# A31G22x register map
Vendor: ABOV Semiconductor Co., Ltd.; Series: A31G22x; File version: 0.2
CPU: CM0PLUS r0p1, little endian, no MPU, no FPU, VTOR, 2 interrupt priority bits
Registers are 32-bit, read-write, reset 0x0 unless marked. A register's access mark holds for its fields unless they carry their own. Offsets are from the block's base; [hi:lo] are bit positions; {n}, {i} and the like mark numbered series.

## SCU — SYSTEM CONTROL UNIT
Base 0x40000000
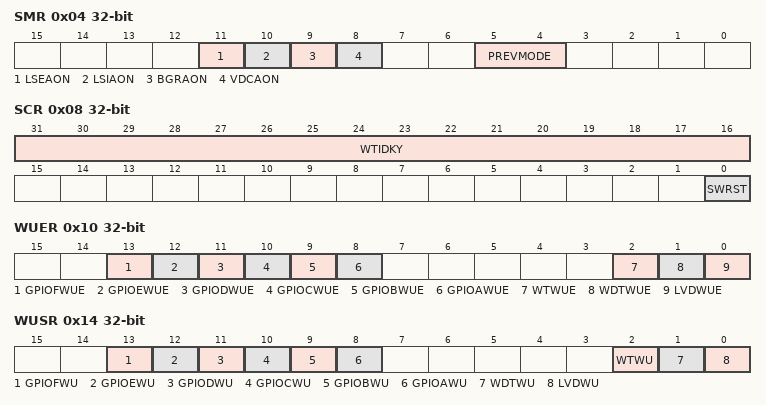
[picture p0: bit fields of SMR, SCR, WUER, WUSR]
0x04 SMR — System Mode Register
  [11] LSEAON — LSE Always on select bit in power down mode 0: LSE is automatically off entering power down mode 1: LSE isn't automatically off entering power down mode
  [10] LSIAON — LSI Always on select bit in power down mode 0: LSI is automatically off entering power down mode 1: LSI isn't automatically off entering power down mode
  [9] BGRAON — BGR Always on select bit in power down mode 0: BGR is automatically off entering power down mode 1: BGR isn't automatically off entering power down mode
  [8] VDCAON — VDC Always on select bit in power down mode
  [5:4] PREVMODE — Previous operating mode before current reset event
0x08 SCR — System Control Register
  [31:16] WTIDKY wo — On writes, write 0x9EB3 to these bits, otherwise the write is ignored.
  [0] SWRST — Internal soft reset activation bit (check RSER[4] for reset)
0x10 WUER — Wake up source enable register
  [13] GPIOFWUE — Enable wakeup source of GPIOF port pin change event
  [12] GPIOEWUE — Enable wakeup source of GPIOE port pin change event
  [11] GPIODWUE — Enable wakeup source of GPIOD port pin change event
  [10] GPIOCWUE — Enable wakeup source of GPIOC port pin change event
  [9] GPIOBWUE — Enable wakeup source of GPIOB port pin change event
  [8] GPIOAWUE — Enable wakeup source of GPIOA port pin change event
  [2] WTWUE — Enable wakeup source of watch timer event
  [1] WDTWUE — Enable wakeup source of watchdog timer event
  [0] LVDWUE — Enable wakeup source of LVD event
0x14 WUSR — Wake up source status register
  [13] GPIOFWU ro — Status of wakeup source of GPIOF port pin change event
  [12] GPIOEWU ro — Status of wakeup source of GPIOE port pin change event
  [11] GPIODWU ro — Status of wakeup source of GPIOD port pin change event
  [10] GPIOCWU ro — Status of wakeup source of GPIOC port pin change event
  [9] GPIOBWU ro — Status of wakeup source of GPIOB port pin change event
  [8] GPIOAWU ro — Status of wakeup source of GPIOA port pin change event
  [2] WTWU ro — Status of wakeup source of watch timer event
  [1] WDTWU ro — Status of wakeup source of watchdog timer event
  [0] LVDWU ro — Status of wakeup source of LVD event
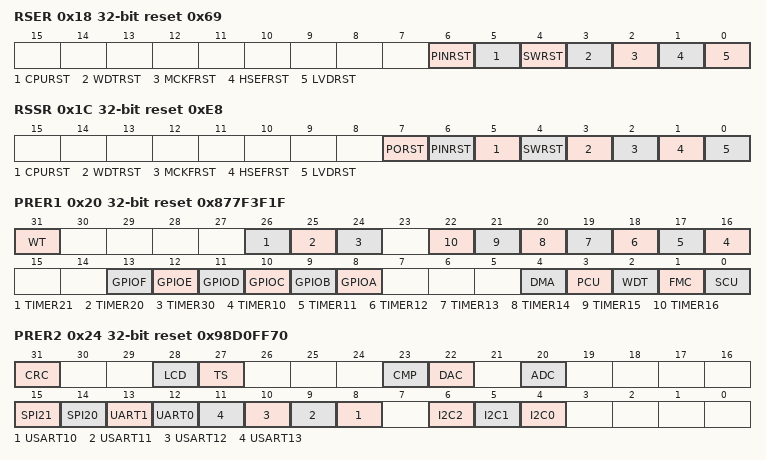
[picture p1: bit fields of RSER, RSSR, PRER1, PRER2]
0x18 RSER reset 0x69 — Reset source enable register
  [6] PINRST — External pin reset enable bit
  [5] CPURST — CPU request reset enable bit
  [4] SWRST — Software reset enable bit
  [3] WDTRST — Watchdog Timer reset enable bit
  [2] MCKFRST — MCLK Clock fail reset enable bit
  [1] HSEFRST — HSE Clock fail reset enable bit
  [0] LVDRST — LVD reset enable bit
0x1C RSSR reset 0xE8 — Reset source status register
  [7] PORST — Power on reset status bit
  [6] PINRST — External pin reset status bit
  [5] CPURST — CPU request reset status bit
  [4] SWRST — Software reset status bit
  [3] WDTRST — Watchdog Timer reset status bit
  [2] MCKFRST — MCLK Clock fail reset status bit
  [1] HSEFRST — HSE Clock fail reset status bit
  [0] LVDRST — LVD reset status bit
0x20 PRER1 reset 0x877F3F1F — Peripheral reset enable register 1
  [31] WT — WT reset mask
  [26] TIMER21 — TIMER21 reset mask
  [25] TIMER20 — TIMER20 reset mask
  [24] TIMER30 — TIMER30 reset mask
  [n+6] TIMER{n} (n=10..16) — TIMER{n} reset mask
  [13] GPIOF — GPIOF reset mask
  [12] GPIOE — GPIOE reset mask
  [11] GPIOD — GPIOD reset mask
  [10] GPIOC — GPIOC reset mask
  [9] GPIOB — GPIOB reset mask
  [8] GPIOA — GPIOA reset mask
  [4] DMA — DMA reset mask
  [3] PCU — PCU reset mask
  [2] WDT — WDT reset mask
  [1] FMC — FMC reset mask
  [0] SCU — SCU reset mask
0x24 PRER2 reset 0x98D0FF70 — Peripheral reset enable register 2
  [31] CRC — CRC reset mask
  [28] LCD — LCD reset enable
  [27] TS — Temperature Sensor reset mask
  [23] CMP — CMP reset mask
  [22] DAC — DAC reset mask
  [20] ADC — ADC reset mask
  [15] SPI21 — SPI21 reset mask
  [14] SPI20 — SPI20 reset mask
  [13] UART1 — UART1 reset mask
  [12] UART0 — UART0 reset mask
  [n-2] USART{n} (n=10..13) — USART{n} reset mask
  [6] I2C2 — I2C2 reset mask
  [5] I2C1 — I2C1 reset mask
  [4] I2C0 — I2C0 reset mask
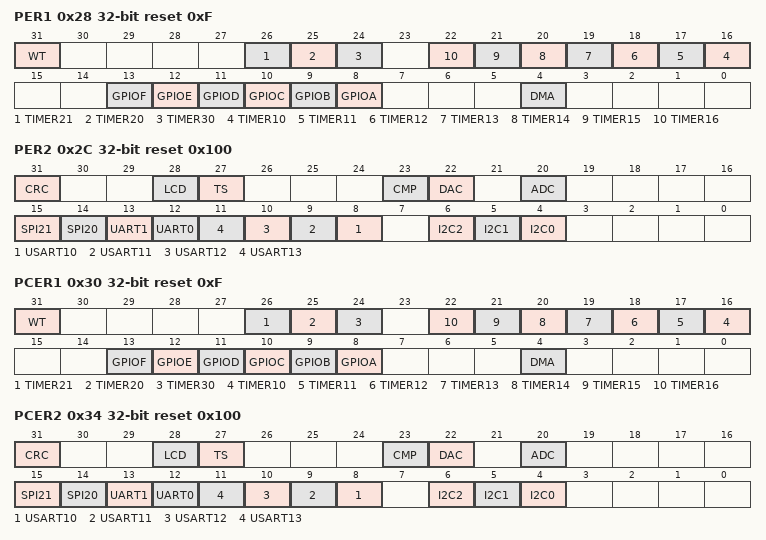
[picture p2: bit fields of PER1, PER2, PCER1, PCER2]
0x28 PER1 reset 0xF — Peripheral enable register 1
  [31] WT — WT function enable
  [26] TIMER21 — TIMER21 function enable
  [25] TIMER20 — TIMER20 function enable
  [24] TIMER30 — TIMER30 function enable
  [n+6] TIMER{n} (n=10..16) — TIMER{n} function enable
  [13] GPIOF — GPIOF function enable
  [12] GPIOE — GPIOE function enable
  [11] GPIOD — GPIOD function enable
  [10] GPIOC — GPIOC function enable
  [9] GPIOB — GPIOB function enable
  [8] GPIOA — GPIOA function enable
  [4] DMA — DMA function enable
0x2C PER2 reset 0x100 — Peripheral enable register 2
  [31] CRC — CRC function enable
  [28] LCD — LCD function enable
  [27] TS — Temperature Sensor function enable
  [23] CMP — CMP function enable
  [22] DAC — DAC function enable
  [20] ADC — ADC function enable
  [15] SPI21 — SPI21 function enable
  [14] SPI20 — SPI20 function enable
  [13] UART1 — UART1 function enable
  [12] UART0 — UART0 function enable
  [n-2] USART{n} (n=10..13) — USART{n} function enable
  [6] I2C2 — I2C2 function enable
  [5] I2C1 — I2C1 function enable
  [4] I2C0 — I2C0 function enable
0x30 PCER1 reset 0xF — Peripheral clock enable register 1
  [31] WT — WT clock enable
  [26] TIMER21 — TIMER21 clock enable
  [25] TIMER20 — TIMER20 clock enable
  [24] TIMER30 — TIMER30 clock enable
  [n+6] TIMER{n} (n=10..16) — TIMER{n} clock enable
  [13] GPIOF — GPIOF clock enable
  [12] GPIOE — GPIOE clock enable
  [11] GPIOD — GPIOD clock enable
  [10] GPIOC — GPIOC clock enable
  [9] GPIOB — GPIOB clock enable
  [8] GPIOA — GPIOA clock enable
  [4] DMA — DMA clock enable
0x34 PCER2 reset 0x100 — Peripheral clock enable register 2
  [31] CRC — CRC clock enable
  [28] LCD — LCD driver clock enable
  [27] TS — Temperature sensor clock enable
  [23] CMP — CMP clock enable
  [22] DAC — DAC clock enable
  [20] ADC — ADC clock enable
  [15] SPI21 — SPI21 clock enable
  [14] SPI20 — SPI20 clock enable
  [13] UART1 — UART1 clock enable
  [12] UART0 — UART0 clock enable
  [n-2] USART{n} (n=10..13) — USART{n} clock enable
  [6] I2C2 — I2C2 clock enable
  [5] I2C1 — I2C1 clock enable
  [4] I2C0 — I2C0 clock enable
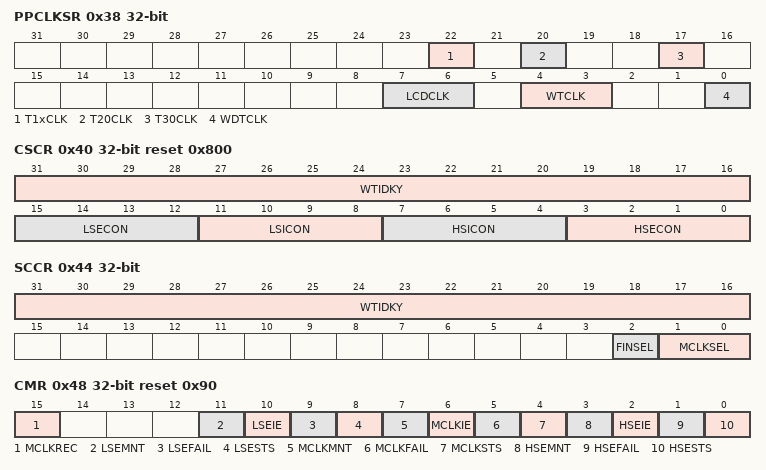
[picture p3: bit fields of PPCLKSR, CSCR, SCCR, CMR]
0x38 PPCLKSR — Peripheral clock selection register
  [22] T1xCLK — Timer 1x Clock Selection bit
  [20] T20CLK — Timer 20 Clock Selection bit
  [17] T30CLK — Timer 30 Clock Selection bit
  [7:6] LCDCLK — LCD Clock Selection bit
  [4:3] WTCLK — Watch Timer Clock Selection bit Note) These bits should be changed during the WTEN bit of watch timer control register (WTCR) is 0b
  [0] WDTCLK — Watch-dog Timer Clock Selection bit
0x40 CSCR reset 0x800 — Clock Source Control register
  [31:16] WTIDKY wo — On writes, write 0xA507 to these bits, otherwise the write is ignored.
  [15:12] LSECON — Low speed external oscillator control
  [11:8] LSICON — Low Speed Internal oscillator control
  [7:4] HSICON — High speed internal oscillator control
  [3:0] HSECON — Hight speed external oscillator control
0x44 SCCR — System Clock Control register
  [31:16] WTIDKY wo — On writes, write 0x570A to these bits, otherwise the write is ignored.
  [2] FINSEL — PLL input source FIN select register
  [1:0] MCLKSEL — System clock select register
0x48 CMR reset 0x90 — Clock Monitoring register
  [15] MCLKREC — MCLK fail auto recovery
  [11] LSEMNT — Low speed External oscillator monitoring enable
  [10] LSEIE — Low speed external oscillator fail interrupt enable
  [9] LSEFAIL — Low speed external oscillator fail interrupt
  [8] LSESTS — Low speed external oscillator status
  [7] MCLKMNT — MCLK monitoring enable
  [6] MCLKIE — MCLK fail interrupt enable
  [5] MCLKFAIL — MCLK fail interrupt
  [4] MCLKSTS — MCLK clock status
  [3] HSEMNT — High speed external oscillator monitoring enable
  [2] HSEIE — High speed external oscillator fail interrupt enable
  [1] HSEFAIL — High speed external oscillator fail interrupt
  [0] HSESTS — High speed external oscillator status
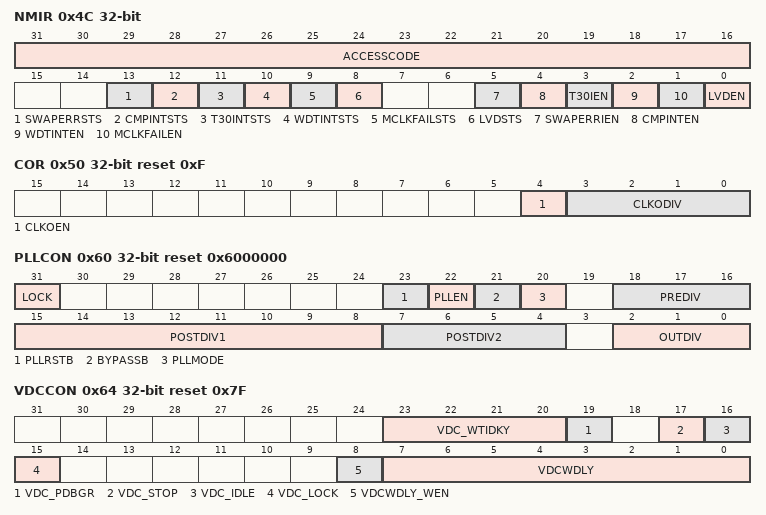
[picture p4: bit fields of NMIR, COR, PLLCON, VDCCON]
0x4C NMIR — NMI control register
  [31:16] ACCESSCODE wo — This field enables writing access to this register. Writing 0xA32C is to enable writing.
  [13] SWAPERRSTS ro — Swap Error Interrupt condition status bit This bit can't invoke NMI interrupt without enable bit
  [12] CMPINTSTS ro — Comparator Interrupt condition status bit This bit can't invoke NMI interrupt without enable bit
  [11] T30INTSTS ro — TIMER30 Interrupt condition status bit This bit can't invoke NMI interrupt without enable bit
  [10] WDTINTSTS ro — WDT Interrupt condition status bit This bit can't invoke NMI interrupt without enable bit
  [9] MCLKFAILSTS ro — MCLK Fail condition status bit This bit can't invoke NMI interrupt without enable bit
  [8] LVDSTS ro — LVD condition status bit This bit can't invoke NMI interrupt without enable bit
  [5] SWAPERRIEN — Swap Error interrupt condition enable for NMI interrupt
  [4] CMPINTEN — Comparator interrupt condition enable for NMI interrupt
  [3] T30IEN — TIMER30 interrupt condition enable for NMI interrupt
  [2] WDTINTEN — WDT Interrupt condition enable for NMI interrupt
  [1] MCLKFAILEN — MCLK Fail condition enable for NMI interrupt
  [0] LVDEN — LVD Fail condition enable for NMI interrupt
0x50 COR reset 0xF — Clock Output Control register
  [4] CLKOEN — Clock output enable
  [3:0] CLKODIV — Clock output divider value CLKO=MCLK (CLKODIV=0) CLKO=MCLK/2(CLKODIV+1) (CLKODIV > 0)
0x60 PLLCON reset 0x6000000 — PLL Control register
  [31] LOCK — LOCK status
  [23] PLLRSTB — PLL reset
  [22] PLLEN — PLL enable
  [21] BYPASSB — FIN bypass
  [20] PLLMODE — PLL VCO mode
  [18:16] PREDIV — FIN predivider FIN divided by (PREDIV + 1), (FIN/1 ~ FIN/8)
  [15:8] POSTDIV1 — Feedback control 1 (N1) N1 = POSTDIV1 + 1
  [7:4] POSTDIV2 — Feedback control 1 (N2) N2 = POSTDIV2 + 1
  [2:0] OUTDIV — output divider control (P) P = OUTDIV + 1
0x64 VDCCON reset 0x7F — VDC Control register
  [23:20] VDC_WTIDKY wo — VDC Write Identification Key On writes, write 0x5 to these bits, otherwise the write is ignored.
  [19] VDC_PDBGR — BGR Buffer Deep-sleep Signal Selection *In BGR on off, VDCLOCK_I should be 0
  [17] VDC_STOP — VDC STOP Mode Control Signal
  [16] VDC_IDLE — VDC STOP1 Mode Control Signal
  [15] VDC_LOCK — VDC VDCLOCK Control Signal for *BGR Stabilization *In BGR off on Sequence, VDCLOCK_I should be 0 during 120usec
  [8] VDCWDLY_WEN wo — VDCWDLY value write enable. VDCWDLY value can be written with writing '1' to VDCWDLY_WEN bit simultaneously.
  [7:0] VDCWDLY — VDC warm-up delay count value. When SCU is waked up from powerdown mode, the warm-up delay is inserted for VDC output being stabilized. The amount of delay can be defined with this register value 7F : 4msec
0x6C LSICON — LSI Control Register
  [0] SKIP_LS — Internal Level Shifter control signal
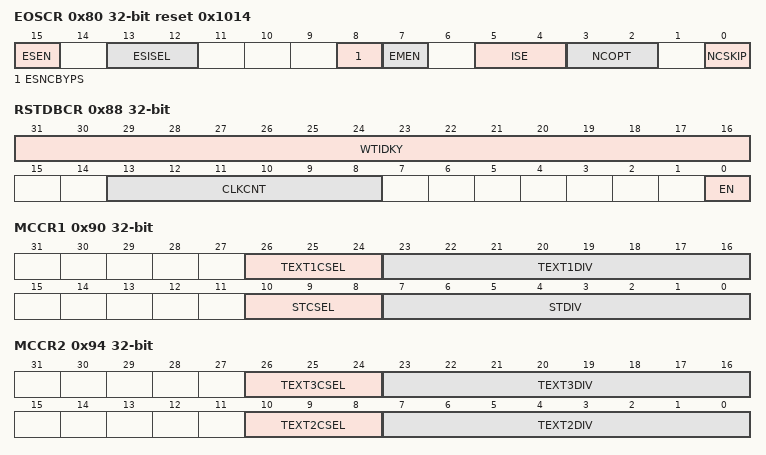
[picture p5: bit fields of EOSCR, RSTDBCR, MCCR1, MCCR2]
0x80 EOSCR reset 0x1014 — External Oscillator control register
  [15] ESEN wo — Write enable for LSE
  [13:12] ESISEL — Select current for LSE
  [8] ESNCBYPS — Noise Cancel Bypass enable for LSE
  [7] EMEN wo — Write enable for HSE
  [5:4] ISE — Select current for HSE
  [3:2] NCOPT — Noise Cancel delay Option for HSE
  [0] NCSKIP — Noise Cancel Skip enable for HSE
0x84 EMODR reset 0x1 — External mode pin read register
  [0] BOOT ro — BOOT pin level
0x88 RSTDBCR — Pin Reset Debounce Control Register
  [31:16] WTIDKY wo — On writes, write 0x0514 to these bits, otherwise the write is ignored.
  [13:8] CLKCNT — Noise cancel delay option for pin reset, N : N clock checking for debounce by LSI(500kHz)
  [0] EN — Pin reset debounce enable bit
0x90 MCCR1 — Miscellaneous Clock Control Register 1
  [26:24] TEXT1CSEL — TIMER1n EXT Clock source select bit
  [23:16] TEXT1DIV — TIMER1n EXT Clock N divider To change the value, set 0x0 first without changing TEXT1CSEL
  [10:8] STCSEL — systick clock source sel
  [7:0] STDIV — SYSTICK Clock N divider To change the value, set 0x0 first without changing STCSEL
0x94 MCCR2 — Miscellaneous Clock Control Register 2
  [26:24] TEXT3CSEL — TIMER 30 EXT Clock source select bit
  [23:16] TEXT3DIV — TIMER 30 EXT Clock N divider To change the value, set 0x0 first without changing TEXT3DIV
  [10:8] TEXT2CSEL
  [7:0] TEXT2DIV — TIMER 20 EXT Clock N divider To change the value, set 0x0 first without changing TEXT2CSEL
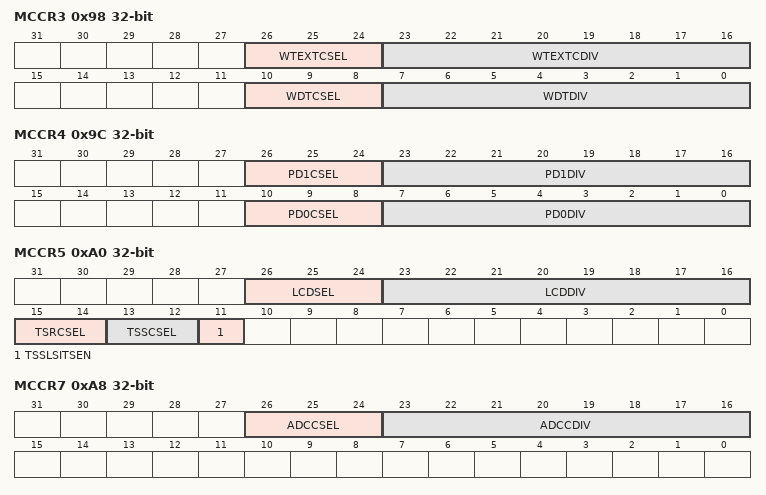
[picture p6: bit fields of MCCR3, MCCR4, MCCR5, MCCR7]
0x98 MCCR3 — Miscellaneous Clock Control Register 3
  [26:24] WTEXTCSEL — WT EXT Clock source select bit
  [23:16] WTEXTCDIV — WT EXT Clock N divider To change the value, set 0x0 first without changing WTEXTCSEL
  [10:8] WDTCSEL — WDT Clock source select bit
  [7:0] WDTDIV — WDT Clock N divider To change the value, set 0x0 first without changing WDTCSEL
0x9C MCCR4 — Miscellaneous Clock Control Register 4
  [26:24] PD1CSEL — Debounce Clock for PORT source select bit (PD,PE,PF)
  [23:16] PD1DIV — PORT Debounce Clock N divider (PD,PE,PF) To change the value, set 0x0 first without changing PD1CSEL
  [10:8] PD0CSEL — Debounce Clock for PORT source select bit (PA,PB,PC)
  [7:0] PD0DIV — PORT Debounce Clock N divider (PA,PB,PC) To change the value, set 0x0 first without changing PD0CSEL
0xA0 MCCR5 — Miscellaneous Clock Control Register 5
  [26:24] LCDSEL — LCD Clock source selection
  [23:16] LCDDIV — LCD Clock N divider
  [15:14] TSRCSEL — Temperature Sensor reference clock selection bit
  [13:12] TSSCSEL — Temperature Sensor sensing clock selection bit
  [11] TSSLSITSEN — Enable temperature sensing oscillator (LSI_TS)
0xA4 MCCR6 — Miscellaneous Clock Control Register 6
0xA8 MCCR7 — Miscellaneous Clock Control Register 7
  [26:24] ADCCSEL — ADC Clock source select bit
  [23:16] ADCCDIV — ADC Clock N divider N must be larger than 0, and the divided clock must be slower than the system clock.
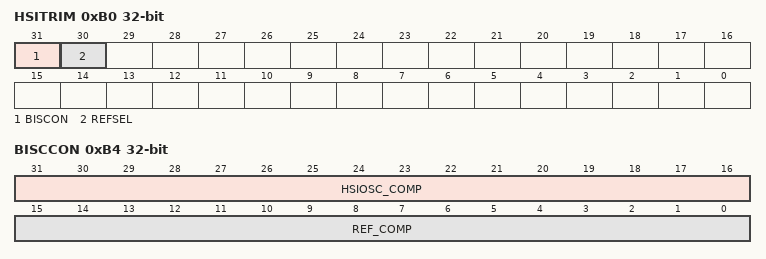
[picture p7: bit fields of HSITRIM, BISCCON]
0xB0 HSITRIM — Internal OSC Trim Register
  [31] BISCON — Built in self calibration function enable
  [30] REFSEL — Reference clock select for self-calibrarion
0xB4 BISCCON — Build in self calibration contrl register
  [31:16] HSIOSC_COMP — Built in self calibration function enable
  [15:0] REF_COMP — Reference clock Compare value
